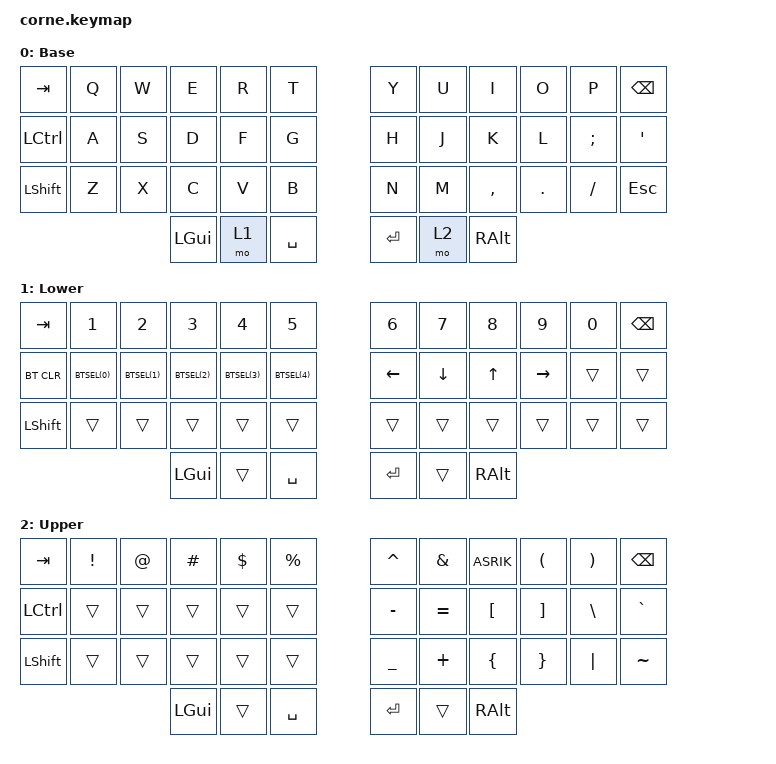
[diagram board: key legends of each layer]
// Macro for `&bt BT_SEL num`
#define BTSEL(num) &bt BT_SEL num

/ {
    keymap {
        compatible = "zmk,keymap";

        base {
            display-name = "Base";

            bindings = <
                &kp TAB     &kp Q       &kp W       &kp E       &kp R       &kp T       &kp Y       &kp U       &kp I       &kp O       &kp P       &kp BSPC
                &kp LCTRL   &kp A       &kp S       &kp D       &kp F       &kp G       &kp H       &kp J       &kp K       &kp L       &kp SEMI    &kp SQT
                &kp LSHFT   &kp Z       &kp X       &kp C       &kp V       &kp B       &kp N       &kp M       &kp COMMA   &kp DOT     &kp FSLH    &kp ESC
                                                    &kp LGUI    &mo 1       &kp SPACE   &kp RET     &mo 2       &kp RALT
            >;
        };

        lower {
            display-name = "Lower";

            bindings = <
                &kp TAB     &kp N1      &kp N2      &kp N3      &kp N4      &kp N5      &kp N6      &kp N7      &kp N8      &kp N9      &kp N0      &kp BSPC
                &bt BT_CLR  BTSEL(0)    BTSEL(1)    BTSEL(2)    BTSEL(3)    BTSEL(4)    &kp LEFT    &kp DOWN    &kp UP      &kp RIGHT   &trans      &trans
                &kp LSHFT   &trans      &trans      &trans      &trans      &trans      &trans      &trans      &trans      &trans      &trans      &trans
                                                    &kp LGUI    &trans      &kp SPACE   &kp RET     &trans      &kp RALT
            >;
        };

        upper {
            display-name = "Upper";

            bindings = <
                &kp  TAB    &kp EXCL    &kp AT      &kp HASH    &kp DLLR    &kp PRCNT   &kp CARET   &kp AMPS    &kp ASRIK   &kp LPAR    &kp RPAR    &kp BSPC
                &kp LCTRL   &trans      &trans      &trans      &trans      &trans      &kp MINUS   &kp EQUAL   &kp LBKT    &kp RBKT    &kp BSLH    &kp GRAVE
                &kp LSHFT   &trans      &trans      &trans      &trans      &trans      &kp UNDER   &kp PLUS    &kp LBRC    &kp RBRC    &kp PIPE    &kp TILDE
                                                    &kp LGUI    &trans      &kp SPACE   &kp RET     &trans      &kp RALT
            >;
        };
  };
};
